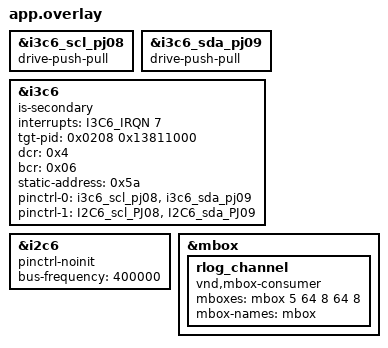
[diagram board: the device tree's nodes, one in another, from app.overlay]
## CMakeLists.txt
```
# SPDX-License-Identifier: Apache-2.0

cmake_minimum_required(VERSION 3.20.0)
find_package(Zephyr REQUIRED HINTS $ENV{ZEPHYR_BASE})
project(cpu1_i3c_target)

# 项目特定源文件
target_sources(app PRIVATE
    src/main.c
    src/i3c_i2c_target_test.c)

# 禁用 cpu1 侧 PA05 toggle 线程（cpu2 用 PA05 做 read 探针标记）
target_compile_definitions(app PRIVATE GPIO_TOGGLE_DISABLE_PA05=1)

# 单出口（SPEC_REFERENCE §6.9.3）：本核是从核 ⇒ token 经 RLOG 交主核打印
target_compile_definitions(app PRIVATE I3C_I2C_SINGLE_EGRESS=1)

# 项目特定include目录
target_include_directories(app PRIVATE
    ${CMAKE_CURRENT_SOURCE_DIR}/../tests/include)

# 包含公共源文件和配置（test_results.c, ztest_glue.c, gpio_toggle.c）
include(${CMAKE_CURRENT_SOURCE_DIR}/../../../common/common_sources.cmake)

# RLOG 单出口（SPEC_REFERENCE §6.9.3）：只在本工程编入 —— 其余工程没有
# `rlog_channel` 设备树节点，编进去会因 DT_NODELABEL 取不到而构建失败。
target_sources(app PRIVATE
    ${CMAKE_CURRENT_SOURCE_DIR}/../../../common/rlog.c)
```

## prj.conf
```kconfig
CONFIG_LOG=y
CONFIG_LOG_MODE_DEFERRED=y
CONFIG_LOG_BUFFER_SIZE=16384
CONFIG_LOG_PROCESS_THREAD_SLEEP_MS=10
CONFIG_SERIAL=y
CONFIG_SHELL=n
CONFIG_ZTEST=y
CONFIG_ZTEST_ASSERT_VERBOSE=1
# R7：n→y——逐项 START/PASS/FAIL 行是 parse_ztest 的数据源（§10.26）
CONFIG_ZTEST_VERBOSE_OUTPUT=y
CONFIG_ZTEST_SUMMARY=n
CONFIG_I3C=y
CONFIG_I3C_USE_IBI=y
CONFIG_I3C_IBI_MAX_PAYLOAD_SIZE=8
CONFIG_I3C_LOG_LEVEL_OFF=y
CONFIG_I2C=y
# i2c6 以 I2C slave 角色响应 i2c5 的访问（普通回调模式，非 BUFFER_MODE）
CONFIG_I2C_TARGET=y
# RLOG 单出口（SPEC_REFERENCE §6.9.3）：从核经 mbox 把 token 交给主核统一打印
CONFIG_MBOX=y
# pinctrl_apply_state() 运行时切换 I3C/I2C 引脚复用（本工程核心机制）
CONFIG_PINCTRL_DYNAMIC=y
CONFIG_PICOLIBC=y
CONFIG_NEWLIB_LIBC=n
CONFIG_MINIMAL_LIBC=n

# GPIO support for PA05/PA07 toggle threads
CONFIG_GPIO=y
```

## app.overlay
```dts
/*
 * I3C/I2C 模块切换测试：target（cpu1）侧总线配置。
 *
 * 被测对象：I3C6（i3c@40094400，I3C target 角色）与 i2c6
 * （i2c@40084400，I2C slave 角色）共用引脚 PJ08/PJ09，模式由引脚
 * 复用（pinctrl）区分：
 *   - "default"     状态 = I3C 引脚复用（i3c6_scl_pj08 / i3c6_sda_pj09）
 *   - "pinmux_i2c"  状态 = I2C 引脚复用（I2C6_scl_PJ08 / I2C6_sda_PJ09）
 *
 * 注意：I2C6 引脚复用节点（I2C6_scl_PJ08 / I2C6_sda_PJ09，pinmux 0x8198/0x8199）
 * 由 soc dtsi（i2c 统一配置块）提供，本工程直接引用，不再自定义；
 * 而 lsqsh_pinctrl_fixed_pinmap.dtsi 中同功能小写节点（i2c6_scl_pj08）已被注释。
 */

/* i2c6 在 soc dtsi 中已有 pinctrl-0（default = I2C 引脚复用），若不置
 * pinctrl-noinit，i2c6 驱动 init 会把引脚切成 I2C 模式，破坏 i3c6 的
 * I3C 默认模式。引脚复用由 i3c6 节点的 pinctrl 双状态统一管理。 */

&i3c6_scl_pj08 {
    drive-push-pull;
};

&i3c6_sda_pj09 {
    drive-push-pull;
};

&i3c6 {
    status = "okay";
    is-secondary;
    interrupts = <I3C6_IRQN 7>;
    tgt-pid = <0x0208 0x13811000>;
    dcr = <0x4>;
    bcr = <0x06>;
    static-address = <0x5a>;

    pinctrl-0 = <
        &i3c6_scl_pj08
        &i3c6_sda_pj09
    >;
    pinctrl-1 = <
        &I2C6_scl_PJ08
        &I2C6_sda_PJ09
    >;
    pinctrl-names = "default", "pinmux_i2c";
};

/* i2c6 复用 I3C6 的引脚（PJ08/PJ09）：pinctrl-noinit 阻止 init 时 apply
 * soc 的 default 状态（I2C 引脚复用），引脚由 i3c6 节点双状态动态切换。
 * i2c6 slave 地址（0x50）由固件 i2c_target_register 时指定。
 * bus-frequency = 400K（与 controller 侧 i2c5 匹配）。 */
&i2c6 {
    status = "okay";
    pinctrl-noinit;
    bus-frequency = <400000>;
};

/* GPIO toggle 使能块统一走公共层（SPEC_REFERENCE §6.1.9 复用收敛）：
 * 使能 GPIOA（PA05/PA07 翻转线程所在端口），label 调整只改公共文件。
 * GPIO toggle 仅 cpu1 使用，cpu2 侧固件不编入 gpio_toggle.c、不 include 本片段。 */
#include "../../../common/gpio_toggle.dtsi"

/* RLOG 单出口通道（SPEC_REFERENCE §6.9.3）：本核（target）的 token 经此通道
 * 交给 controller 统一打印，本核串口不再出 token（LOG/panic 仍走本地）。
 * `channel` 单元格必须等于本节点在 `&mbox` 子节点中的**序号**（驱动按
 * DT_INST_FOREACH_CHILD_STATUS_OKAY 的遍历序索引 FIFO，spec 的 channel_id
 * 直接当数组下标），以 zephyr.dts 里 `&mbox` 的子节点顺序为准：板级现有
 * 5 个 consumer（0..4），本项目追加 ⇒ 序号 5。两核必须一致。
 * 宽 64 与 RLOG 帧长（63B）匹配；深度 8 覆盖从核一拍内的连发。 */
&mbox {
	rlog_channel: rlog_channel {
		compatible = "vnd,mbox-consumer";
		mboxes = <&mbox 5 64 8 64 8>;
		mbox-names = "mbox";
	};
};
```

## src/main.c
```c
/*
 * Copyright (c) 2026 LinkedSemi
 *
 * SPDX-License-Identifier: Apache-2.0
 */

#include "i3c_i2c_target_test.h"
#include "i3c_i2c_switch_test_protocol.h"
#include "test_results.h"
#include "ztest_glue.h"

#include <stdio.h>
#include <string.h>
#include <zephyr/kernel.h>
#include <zephyr/device.h>
#include <zephyr/drivers/i3c.h>
#include <zephyr/logging/log.h>

LOG_MODULE_REGISTER(i3c_i2c_target_test, LOG_LEVEL_INF);

#ifndef CONFIG_I3C_I2C_PURE_I2C_TEST
const struct device *tgt_i3c_dev = DEVICE_DT_GET(DT_NODELABEL(i3c6));
#endif
const struct device *tgt_i2c_dev = DEVICE_DT_GET(DT_NODELABEL(i2c6));
uint8_t tgt_tx_buf[256];

void test_main(void)
{
	/* 单出口（SPEC_REFERENCE §6.9.3）：本核是**从核** ⇒ 不往自己的串口打
	 * token。先开 RLOG 发送通道，引导标记与逐项 token 全部经 mbox 交主核
	 * 原样打印。本核的 LOG / panic / assert 文本不走 RLOG ⇒ 崩溃现场仍留在
	 * 本地串口上。 */
	rlog_secondary_init();
	I3C_I2C_TGT_BOOT();

	LOG_INF("[CPU1 I3C_I2C_TGT] target test started");

	for (int i = 0; i < (int)sizeof(tgt_tx_buf); i++) {
		tgt_tx_buf[i] = (uint8_t)(TGT_READ_PATTERN_BASE + i);
	}

	target_test_init();
	target_dispatcher_run();

	/* dispatcher 在收到 CMD_PRINT_SUMMARY 后退出（tgt_done 标志）；
	 * 检查 test_results[] 判定本核全部项是否 PASS。 */
	bool any_fail = false;
	for (int i = 0; i < I3C_I2C_TEST_COUNT; i++) {
		if (test_results[i] == TR_FAIL) {
			any_fail = true;
			break;
		}
	}
	/* 收尾 DONE 帧必须是整条流的**最后一条**：主核等到它才打印自己的
	 * PROJECT EXECUTION（否则 harness 会因为"已见完成标记"提前杀 gdb、
	 * 截断从核结果）。行首带 `I3C_I2C_TEST:TGT:` ⇒ 采集侧按前缀分拣回
	 * serial_TGT.log，重放仍是两核各自成表（§6.9.4）。 */
	rlog_emit_done(!any_fail, any_fail
		? "I3C_I2C_TEST:TGT:PROJECT EXECUTION FAILED"
		: "I3C_I2C_TEST:TGT:PROJECT EXECUTION SUCCESSFUL");

	/* test_main 不得返回（CLAUDE.md §4.1）：返回会进 ztest 强 main() 的
	 * `TC_END_REPORT`，在本核串口补打 `====` + 一条**本地**
	 * `PROJECT EXECUTION` —— 那既是本核单出口的漏点（从核又自己出了收尾
	 * token），也让主核流里多出一条早于从核 DONE 的完成标记。 */
	k_sleep(K_FOREVER);
}
```

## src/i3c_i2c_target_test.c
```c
/*
 * Copyright (c) 2026 LinkedSemi
 *
 * SPDX-License-Identifier: Apache-2.0
 *
 * I3C/I2C 模块切换测试 —— cpu1 target 侧。
 *
 * 同一硬件模块（I3C6）以两个驱动视图存在：i3c6（I3C target）+ i2c6（I2C slave），
 * 引脚复用由 i3c6 节点的 pinctrl 双状态决定，本固件按 controller 命令经
 * pinctrl_apply_state() 在 "default"(I3C) 与 "pinmux_i2c"(I2C) 间切换。
 *
 * I3C 与 I2C 两种模式的 target 回调共用同一套逐字节解析状态机：
 *   - 命令通道：'B' <id> 开始记账 / 'E' <id> 结账 / 'W' <len> <data> 写 pattern 校验
 *   - 切换通道：'S' 切 I2C / 'Y' 切回 I3C（经延时后应用，避总线竞态）
 *   - 收尾通道：'P' 打印 SUMMARY
 *
 * ISR 回调（write_received 等）只解析记账 + 塞事件队列，所有 token 打印
 * 都在 dispatcher 线程上下文（CLAUDE.md §4.2 ISR 禁 LOG）。
 */

#include "i3c_i2c_target_test.h"
#include "i3c_i2c_switch_test_protocol.h"
#include "test_results.h"

#include <stdbool.h>
#include <stdio.h>
#include <string.h>
#include <zephyr/kernel.h>
#include <zephyr/drivers/i3c.h>
#include <zephyr/drivers/i2c.h>
#include <zephyr/drivers/pinctrl.h>
#include <zephyr/logging/log.h>
#include <zephyr/sys/printk.h>
#include <reg_i3c.h>
#include <zephyr/devicetree.h>

LOG_MODULE_REGISTER(i3c_i2c_target_test_impl, LOG_LEVEL_INF);

/* tgt_apply_switch 切回 I3C 时重注册用（target_test_init 中赋值） */
struct i3c_target_config *tgt_i3c_cfg_ptr;

/* ============ 常量 ============ */

/* I3C 读长度：controller 固定读 16 字节（≤ I3C TX FIFO 深度），
 * I3C 侧读回调据此判 END0（最后字节）；I2C 侧长度由 controller 的 STOP 决定。 */
#define TGT_TX_LEN 16U

/* 事件队列：ISR 只塞队列（K_NO_WAIT），dispatcher 线程消费并打印 */
enum tgt_evt_type {
	TGT_EVT_BEGIN,		/* 'B' <id>：开始记账 */
	TGT_EVT_END,		/* 'E' <id>：结账 */
	TGT_EVT_SWITCH,		/* 'S'/'Y'：切换 pinmux（id=1 切 I2C，0 切回 I3C） */
	TGT_EVT_NACK_WINDOW,	/* 'N'：临时置 SLVNACK 制造广播 NACK 窗口（复现用） */
	TGT_EVT_SUMMARY,	/* 'P'：打印 SUMMARY */
};

struct tgt_event {
	enum tgt_evt_type type;
	uint8_t id;
};

K_MSGQ_DEFINE(tgt_event_msgq, sizeof(struct tgt_event), 8, 4);

/* ============ 共享状态（ISR 记账，dispatcher 消费） ============ */

/* 纯 I2C case（CONFIG_I3C_I2C_PURE_I2C_TEST）禁用 i3c6，无 pinctrl 结构体 */
#ifndef CONFIG_I3C_I2C_PURE_I2C_TEST
PINCTRL_DT_DEV_CONFIG_DECLARE(DT_NODELABEL(i3c6));
static const struct pinctrl_dev_config *tgt_pcfg =
	PINCTRL_DT_DEV_CONFIG_GET(DT_NODELABEL(i3c6));
#endif

/* 读序列索引：每次写匹配复位 0，read 回调逐字节推进 */
static volatile uint16_t tgt_tx_idx;

/* 逐字节解析状态机 */
enum parse_state {
	PS_OPCODE,		/* 等 opcode */
	PS_CMD_BEGIN,		/* 已收 'B'，等 test id */
	PS_CMD_END,		/* 已收 'E'，等 test id */
	PS_WRITE_LEN,		/* 已收 'W'，等长度 */
	PS_WRITE_DATA,		/* 已收 'W' <len>，收数据并校验 */
};

static volatile enum parse_state tgt_ps;
static volatile uint8_t tgt_wr_len;
static volatile uint16_t tgt_wr_idx;

/* 写 pattern 内容校验：期望字节为递增序列 0,1,2,... */
static volatile bool tgt_data_mismatch;

/* 当前测试 id 与失败累计：同 id 多轮 begin 不清失败（STRESS 任一轮失败即败） */
static volatile uint8_t tgt_cur_id;
static volatile uint8_t tgt_last_id;
static volatile bool tgt_failed;
static char tgt_fail_reason[TR_REASON_LEN];

/* ============ 逐字节解析（ISR 上下文：只记账 + 塞队列） ============ */

static volatile bool tgt_evt_overflow;	/* 事件队列满（不应发生，协议单帧 ≤ 4 事件） */
static volatile bool tgt_done;		/* SUMMARY 后置 true，dispatcher 退出 */

static void tgt_queue_event(enum tgt_evt_type type, uint8_t id)
{
	struct tgt_event ev = { .type = type, .id = id };

	if (k_msgq_put(&tgt_event_msgq, &ev, K_NO_WAIT) != 0) {
		tgt_evt_overflow = true;
	}
}

static void tgt_parse_byte(uint8_t byte)
{
	switch (tgt_ps) {
	case PS_OPCODE:
		switch (byte) {
		case CMD_TGT_BEGIN:
			tgt_ps = PS_CMD_BEGIN;
			break;
		case CMD_TGT_END:
			tgt_ps = PS_CMD_END;
			break;
		case CMD_SWITCH_TO_I2C:
		case CMD_SWITCH_TO_I3C:
			tgt_queue_event(TGT_EVT_SWITCH,
					 (byte == CMD_SWITCH_TO_I2C) ? 1U : 0U);
			break;
		case CMD_NACK_WINDOW:
			tgt_queue_event(TGT_EVT_NACK_WINDOW, 0U);
			break;
		case CMD_WRITE_PATTERN:
			tgt_ps = PS_WRITE_LEN;
			break;
		case CMD_PRINT_SUMMARY:
			tgt_queue_event(TGT_EVT_SUMMARY, 0U);
			break;
		default:
			break;	/* 未知 opcode 忽略，保持等 opcode */
		}
		break;
	case PS_CMD_BEGIN:
		tgt_queue_event(TGT_EVT_BEGIN, byte);
		tgt_ps = PS_OPCODE;
		break;
	case PS_CMD_END:
		tgt_queue_event(TGT_EVT_END, byte);
		tgt_ps = PS_OPCODE;
		break;
	case PS_WRITE_LEN:
		tgt_wr_len = byte;
		tgt_wr_idx = 0;
		tgt_ps = (byte == 0) ? PS_OPCODE : PS_WRITE_DATA;
		break;
	case PS_WRITE_DATA:
		if (byte != (uint8_t)tgt_wr_idx) {
			tgt_data_mismatch = true;
		}
		if (++tgt_wr_idx >= tgt_wr_len) {
			tgt_ps = PS_OPCODE;
		}
		break;
	}
}

static void tgt_reset_rx(void)
{
	tgt_ps = PS_OPCODE;
	tgt_wr_len = 0;
	tgt_wr_idx = 0;
}

/* ============ I3C6 target 回调（纯 I2C case 无 I3C 侧） ============ */

#ifndef CONFIG_I3C_I2C_PURE_I2C_TEST
/* I3C 读字节：tx_idx < TGT_TX_LEN 时供数据，最后字节返回 1（驱动标 END0）；
 * 已预填 FIFO（16B 整满）时返回 0 字节并声明数据结束（样板同语义）。 */
static int tgt_i3c_read_byte(uint8_t *val)
{
	if (tgt_tx_idx < TGT_TX_LEN) {
		*val = tgt_tx_buf[tgt_tx_idx++];
		if (tgt_tx_idx >= TGT_TX_LEN) {
			return 1;
		}
		return 0;
	}

	*val = 0;
	return 1;
}

/* FIFO 预填：装 16 字节（= FIFO 深度，末字节带 END0 由硬件发完）。
 * 预填时机（三个）：
 *   1) write_requested_cb（写匹配）：restart 读请求时 FIFO 已满；
 *   2) stop_cb（每笔传输结束）：驱动 ISR 的 STOP 分支 FLUSHTB 清空 TX
 *      FIFO，必须重填，否则下一笔独立读传输（START+addr+R）开始时
 *      FIFO 空，read_requested_cb 会被调且只能提供 END0 → 只发 1 字节，
 *      controller 读欠载报错（实测 i3c_baseline read:-5）；
 *   3) init：总线空闲时恢复 FIFO 常备数据。
 * 驱动按 FIFO 现存 TXCOUNT 续写，重复预填幂等（样板同语义）。 */
static void tgt_i3c_prefill_tx(void)
{
	int pre = i3c_target_tx_write(tgt_i3c_dev, tgt_tx_buf, TGT_TX_LEN, 0);

	if (pre > 0) {
		tgt_tx_idx = (uint16_t)pre;
	}
}

static int tgt_i3c_write_requested_cb(struct i3c_target_config *config)
{
	ARG_UNUSED(config);

	tgt_reset_rx();
	tgt_tx_idx = 0;
	tgt_i3c_prefill_tx();
	return 0;
}

static int tgt_i3c_write_received_cb(struct i3c_target_config *config, uint8_t val)
{
	ARG_UNUSED(config);

	tgt_parse_byte(val);
	return 0;
}

static int tgt_i3c_read_requested_cb(struct i3c_target_config *config, uint8_t *val)
{
	ARG_UNUSED(config);

	return tgt_i3c_read_byte(val);
}

static int tgt_i3c_read_processed_cb(struct i3c_target_config *config, uint8_t *val)
{
	ARG_UNUSED(config);

	return tgt_i3c_read_byte(val);
}

static int tgt_i3c_stop_cb(struct i3c_target_config *config)
{
	ARG_UNUSED(config);

	/* 驱动 ISR 的 STOP 分支已 FLUSHTB 清空 TX FIFO，必须重填，
	 * 使下一笔独立读传输（START+addr+R）开始时 FIFO 已满（见
	 * tgt_i3c_prefill_tx 注释）；FIFO 有数据时驱动读分支不调
	 * read_requested_cb，硬件直接发预填数据。 */
	tgt_reset_rx();
	tgt_i3c_prefill_tx();
	return 0;
}
#endif /* !CONFIG_I3C_I2C_PURE_I2C_TEST */

/* ============ I2C6 slave 回调（逐字节，与 I3C 回调共用解析状态机） ============ */

static int tgt_i2c_read_byte(uint8_t *val)
{
	/* i2c 无 END0 概念：读长度由 controller 的 STOP 决定，tx_buf[256] 足够 */
	*val = tgt_tx_buf[tgt_tx_idx++];
	return 0;
}

static int tgt_i2c_write_requested_cb(struct i2c_target_config *config)
{
	ARG_UNUSED(config);

	tgt_reset_rx();
	tgt_tx_idx = 0;
	return 0;
}

static int tgt_i2c_write_received_cb(struct i2c_target_config *config, uint8_t val)
{
	ARG_UNUSED(config);

	tgt_parse_byte(val);
	return 0;	/* 不 NACK：数据内容由解析状态机校验 */
}

static int tgt_i2c_read_requested_cb(struct i2c_target_config *config, uint8_t *val)
{
	ARG_UNUSED(config);

	return tgt_i2c_read_byte(val);
}

static int tgt_i2c_read_processed_cb(struct i2c_target_config *config, uint8_t *val)
{
	ARG_UNUSED(config);

	return tgt_i2c_read_byte(val);
}

static int tgt_i2c_stop_cb(struct i2c_target_config *config)
{
	ARG_UNUSED(config);

	tgt_reset_rx();
	return 0;
}

/* ============ dispatcher 线程：事件处理（token 打印唯一位置） ============ */

static void tgt_handle_begin(uint8_t id)
{
	if (id >= I3C_I2C_TEST_COUNT) {
		return;
	}

	I3C_I2C_TGT_START_VAR(i3c_i2c_test_names[id]);

	tgt_cur_id = id;
	tgt_tx_idx = 0;
	if (id != tgt_last_id) {
		/* 新测试清失败累计；同 id 多轮 begin（STRESS）不清 */
		tgt_failed = false;
		tgt_fail_reason[0] = '\0';
		/* 写内容校验标志同口径**粘滞**（仅换测试项时清）：
		 * STRESS 每轮发 3 次 'B'（I3C→I2C→I3C 三个子轮）却只在轮末 'E'
		 * 判账。原实现每次 begin 都清 tgt_data_mismatch ⇒ 前 2 个子轮的写
		 * 通道损坏被后一次 begin 抹掉，TGT 侧永远抓不到；而 CTRL 侧
		 * ctrl_failed 是同 id 粘滞（ctrl_test_begin），两侧口径不一致会让
		 * "双核双 PASS"里的 TGT 一半失去判别力。改后本项内所有 'B' 子轮的
		 * 失配都会累积到轮末 'E' 一并判账。 */
		tgt_data_mismatch = false;
		tgt_last_id = id;
	}
}

static void tgt_handle_end(uint8_t id)
{
	if (id >= I3C_I2C_TEST_COUNT) {
		return;
	}

	if (id != tgt_cur_id) {
		I3C_I2C_TGT_FAIL_VAR(i3c_i2c_test_names[id], "end_id_mismatch");
		tr_record(id, TR_FAIL, "end_id_mismatch");
		return;
	}

	if (tgt_data_mismatch) {
		tgt_failed = true;
		snprintk(tgt_fail_reason, sizeof(tgt_fail_reason),
			 "write_data_mismatch");
	}

	if (tgt_failed) {
		I3C_I2C_TGT_FAIL_VAR(i3c_i2c_test_names[id], tgt_fail_reason);
		tr_record(id, TR_FAIL, "%s", tgt_fail_reason);
	} else {
		I3C_I2C_TGT_PASS_VAR(i3c_i2c_test_names[id]);
		tr_record(id, TR_PASS, "");
	}
}

#ifndef CONFIG_I3C_I2C_PURE_I2C_TEST

static void tgt_apply_switch(bool to_i2c)
{
	uint32_t state_id = to_i2c ? PINCTRL_STATE_PINMUX_I2C
				   : PINCTRL_STATE_DEFAULT;
	int ret = pinctrl_apply_state(tgt_pcfg, state_id);

	if (ret != 0) {
		tgt_failed = true;
		snprintk(tgt_fail_reason, sizeof(tgt_fail_reason),
			 "pinctrl_apply_state(%s):%d", to_i2c ? "i2c" : "i3c", ret);
	} else if (!to_i2c) {
		/* 切回 I3C：SLVENA 复位清硬件状态 + FLUSHTB 清 TX FIFO 残留，
		 * 再重注册回调 + 重预填 16B pattern（恢复正式工作状态）。 */
		I3C_TypeDef *base = (I3C_TypeDef *)DT_REG_ADDR(DT_NODELABEL(i3c6));

		base->SCONFIG &= ~I3C_SCONFIG_SLVENA_MASK;
		k_busy_wait(10);
		base->SCONFIG |= I3C_SCONFIG_SLVENA_MASK;
		k_busy_wait(10);

		i3c_target_unregister(tgt_i3c_dev, tgt_i3c_cfg_ptr);
		base->SDATACTRL |= I3C_SDATACTRL_FLUSHTB_MASK;
		i3c_target_register(tgt_i3c_dev, tgt_i3c_cfg_ptr);
		for (int i = 0; i < (int)sizeof(tgt_tx_buf); i++) {
			tgt_tx_buf[i] = (uint8_t)(TGT_READ_PATTERN_BASE + i);
		}
		tgt_tx_idx = 0;
		tgt_i3c_prefill_tx();
	}
}

/* NACK 窗口：切 I2C pinmux 让 target 不响应 I3C 广播（CE2），延时
 * NACK_WINDOW_MS 后自动切回 I3C（不产生 I2C 帧，无需 'Y' 命令）。
 *
 * ⚠️ 必须先延时 TGT_SWITCH_DELAY_MS 再切，与 TGT_EVT_SWITCH 同款：
 *   controller 侧按「dispatcher(~1ms) + TGT_SWITCH_DELAY_MS(5ms) ⇒ 窗口起点 ~6ms」
 *   的模型决定何时发广播 NACK。若这里不延时，窗口实际落在 [~1, ~3]ms，
 *   而 controller 到 ~6ms 才发 ⇒ 到达时 target 早已切回 I3C ⇒
 *   `broadcast_nack_recovery` 收不到期望的 NACK（实测 3/3 确定性失败）。 */
static void tgt_enter_nack_window(void)
{
	k_sleep(K_MSEC(TGT_SWITCH_DELAY_MS));	/* 与 controller 的时序模型对齐 */
	tgt_apply_switch(true);		/* 切 I2C，不响应 I3C 广播 */
	k_sleep(K_MSEC(NACK_WINDOW_MS));
	tgt_apply_switch(false);	/* 自动切回 I3C */
}
#endif

static void tgt_print_summary(void)
{
	uint8_t passed = 0;

	I3C_I2C_SUMMARY_BEGIN(TGT);
	for (int i = 0; i < I3C_I2C_TEST_COUNT; i++) {
		switch (test_results[i]) {
		case TR_PASS:
			I3C_I2C_SUMMARY_ITEM(TGT, i3c_i2c_test_names[i], "PASS");
			passed++;
			break;
		case TR_FAIL:
			I3C_I2C_SUMMARY_ITEM_REASON(TGT, i3c_i2c_test_names[i],
						     "FAIL", test_reasons[i]);
			break;
		default:
			I3C_I2C_SUMMARY_ITEM(TGT, i3c_i2c_test_names[i], "NOT_RUN");
			break;
		}
	}
	I3C_I2C_SUMMARY_END(TGT, passed, I3C_I2C_TEST_COUNT);
	I3C_I2C_TGT_DONE_VAR(passed == I3C_I2C_TEST_COUNT ? "PASS" : "FAIL");
}

static void dispatcher_entry(void *p1, void *p2, void *p3)
{
	ARG_UNUSED(p1);
	ARG_UNUSED(p2);
	ARG_UNUSED(p3);

	while (true) {
		struct tgt_event ev;
		int ret = k_msgq_get(&tgt_event_msgq, &ev, K_FOREVER);

		if (ret != 0) {
			continue;
		}

		switch (ev.type) {
		case TGT_EVT_BEGIN:
			tgt_handle_begin(ev.id);
			break;
		case TGT_EVT_END:
			tgt_handle_end(ev.id);
			break;
		case TGT_EVT_SWITCH:
#ifndef CONFIG_I3C_I2C_PURE_I2C_TEST
			/* 延时再切：保证 controller 已停止总线操作（协议时序） */
			k_sleep(K_MSEC(TGT_SWITCH_DELAY_MS));
			tgt_apply_switch(ev.id != 0);
#else
			/* 纯 I2C case 无切换命令（'S'/'Y' 不应到达） */
			break;
#endif
			break;
		case TGT_EVT_NACK_WINDOW:
#ifndef CONFIG_I3C_I2C_PURE_I2C_TEST
			tgt_enter_nack_window();
#else
			break;
#endif
			break;
		case TGT_EVT_SUMMARY:
			tgt_print_summary();
			tgt_done = true;
			break;
		}
		if (tgt_done) {
			break;	/* SUMMARY 已打印，dispatcher 退出，test_main 继续 */
		}
	}
}

/* ============ 公共 init / dispatcher 入口 ============ */

#ifndef CONFIG_I3C_I2C_PURE_I2C_TEST
/* pinctrl_states：双核各自自主验证（不经总线命令），验证 IO 区分机制静态配置 */
static void tgt_self_check_pinctrl_states(void)
{
	I3C_I2C_TGT_START("pinctrl_states");

	bool ok = (tgt_pcfg->state_cnt == 2) &&
		  (tgt_pcfg->states[0].id == PINCTRL_STATE_DEFAULT) &&
		  (tgt_pcfg->states[1].id == PINCTRL_STATE_PINMUX_I2C);

	if (ok) {
		I3C_I2C_TGT_PASS("pinctrl_states");
		tr_record(TEST_PINCTRL_STATES, TR_PASS, "");
	} else if (tgt_pcfg->state_cnt >= 2) {
		snprintk(tgt_fail_reason, sizeof(tgt_fail_reason),
			 "states:%u[%u,%u]", tgt_pcfg->state_cnt,
			 tgt_pcfg->states[0].id, tgt_pcfg->states[1].id);
		I3C_I2C_TGT_FAIL_VAR("pinctrl_states", tgt_fail_reason);
		tr_record(TEST_PINCTRL_STATES, TR_FAIL, "%s", tgt_fail_reason);
	} else {
		/* 守卫：state_cnt < 2 时 states[1] 越界（原实现无条件读
		 * states[0]/states[1]，state_cnt<2 属内存安全缺陷）。 */
		snprintk(tgt_fail_reason, sizeof(tgt_fail_reason),
			 "state_cnt:%u (<2)", tgt_pcfg->state_cnt);
		I3C_I2C_TGT_FAIL_VAR("pinctrl_states", tgt_fail_reason);
		tr_record(TEST_PINCTRL_STATES, TR_FAIL, "%s", tgt_fail_reason);
	}
}
#endif

void target_test_init(void)
{
	/* 标准 Zephyr i2c_target_callbacks：不设 buf_read_requested（NULL），
	 * 驱动按函数指针非 NULL 判断走逐字节回调路径（i2c_ls.c）。 */
	static struct i2c_target_callbacks i2c_cb = {
		.write_requested = tgt_i2c_write_requested_cb,
		.write_received = tgt_i2c_write_received_cb,
		.read_requested = tgt_i2c_read_requested_cb,
		.read_processed = tgt_i2c_read_processed_cb,
		.stop = tgt_i2c_stop_cb,
	};
	static struct i2c_target_config i2c_cfg = {
		.address = I2C_TGT_SLAVE_ADDR,
		.callbacks = &i2c_cb,
	};

	tgt_reset_rx();
	tgt_failed = false;
	tgt_fail_reason[0] = '\0';

	tr_init(I3C_I2C_TEST_COUNT);

#ifndef CONFIG_I3C_I2C_PURE_I2C_TEST
	static struct i3c_target_callbacks i3c_cb = {
		.write_requested_cb = tgt_i3c_write_requested_cb,
		.write_received_cb = tgt_i3c_write_received_cb,
		.read_requested_cb = tgt_i3c_read_requested_cb,
		.read_processed_cb = tgt_i3c_read_processed_cb,
		.stop_cb = tgt_i3c_stop_cb,
	};
	static struct i3c_target_config i3c_cfg = {
		.address = I3C_SWITCH_TARGET_ADDR,
		.callbacks = &i3c_cb,
	};
	/* 供 tgt_apply_switch 重注册用 */
	tgt_i3c_cfg_ptr = &i3c_cfg;

	int ret = i3c_target_register(tgt_i3c_dev, &i3c_cfg);
	if (ret != 0) {
		LOG_ERR("i3c_target_register failed: %d", ret);
	}

	/* init 预填：总线空闲时恢复 FIFO 常备数据（与 stop_cb 预填同语义） */
	tgt_i3c_prefill_tx();

	ret = i2c_target_register(tgt_i2c_dev, &i2c_cfg);
	if (ret != 0) {
		LOG_ERR("i2c_target_register failed: %d", ret);
	}
#else
	int ret = i2c_target_register(tgt_i2c_dev, &i2c_cfg);
	if (ret != 0) {
		LOG_ERR("i2c_target_register failed: %d", ret);
	}
#endif
}

void target_dispatcher_run(void)
{
	static K_THREAD_STACK_DEFINE(dispatcher_stack, 4096);
	static struct k_thread dispatcher_thread;

#ifndef CONFIG_I3C_I2C_PURE_I2C_TEST
	tgt_self_check_pinctrl_states();
#endif

	k_thread_create(&dispatcher_thread, dispatcher_stack,
			K_THREAD_STACK_SIZEOF(dispatcher_stack),
			dispatcher_entry, NULL, NULL, NULL,
			7, 0, K_NO_WAIT);
	/* 同步 join：test_main 不得返回（CLAUDE.md §4.1） */
	k_thread_join(&dispatcher_thread, K_FOREVER);
}
```

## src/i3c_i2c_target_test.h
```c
/*
 * Copyright (c) 2026 LinkedSemi
 *
 * SPDX-License-Identifier: Apache-2.0
 */

#ifndef I3C_I2C_TARGET_TEST_H
#define I3C_I2C_TARGET_TEST_H

#include <stdint.h>
#include <stddef.h>
#include <zephyr/device.h>

#ifdef __cplusplus
extern "C" {
#endif

/* i3c6：I3C target（I3C 模式）；i2c6：I2C slave（I2C 模式，同一模块两个驱动视图） */
#ifndef CONFIG_I3C_I2C_PURE_I2C_TEST
extern const struct device *tgt_i3c_dev;
#endif
extern const struct device *tgt_i2c_dev;

/* 读预填数据缓冲（0xAA + i），i3c/i2c 读回调共用 */
extern uint8_t tgt_tx_buf[256];

void target_test_init(void);
void target_dispatcher_run(void);

#ifdef __cplusplus
}
#endif

#endif /* I3C_I2C_TARGET_TEST_H */
```
